# MKE15Z7 register map
Vendor: Freescale Semiconductor, Inc.; Series: Kinetis_E; File version: 1.6
CPU: CM0PLUS r0p0, little endian, no MPU, no FPU, VTOR, 2 interrupt priority bits
Registers are 32-bit, read-write, reset 0x0 unless marked. A register's access mark holds for its fields unless they carry their own. Offsets are from the block's base; [hi:lo] are bit positions.

## PWT — Pulse Width Timer
Base 0x40056000; register names take the prefix PWT_
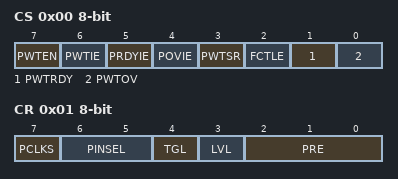
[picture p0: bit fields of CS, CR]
0x00 CS 8-bit — Pulse Width Timer Control and Status Register
  [7] PWTEN — PWT Module Enable
    0=The PWT is disabled; 1=The PWT is enabled
  [6] PWTIE — PWT Module Interrupt Enable
    0=Disables the PWT to generate interrupt; 1=Enables the PWT to generate interrupt
  [5] PRDYIE — PWT Pulse Width Data Ready Interrupt Enable
    0=Disable PWT to generate interrupt when PWTRDY is set; 1=Enable PWT to generate interrupt when PWTRDY is set
  [4] POVIE — PWT Counter Overflow Interrupt Enable
    0=Disable PWT to generate interrupt when PWTOV is set; 1=Enable PWT to generate interrupt when PWTOV is set
  [3] PWTSR wo — PWT Soft Reset
    0=No action taken; 1=Writing 1 to this field will perform soft reset to PWT
  [2] FCTLE — First counter load enable after enable
    0=Do not load the first counter values to corresponding registers; 1=Load the first coutner value to corresponding registers depended by the PWTIN level
  [1] PWTRDY — PWT Pulse Width Valid
    0=PWT pulse width register(s) is not up-to-date; 1=PWT pulse width register(s) has been updated
  [0] PWTOV — PWT Counter Overflow
    0=PWT counter no overflow; 1=PWT counter runs from 0xFFFF to 0x0000
0x01 CR 8-bit — Pulse Width Timer Control Register
  [7] PCLKS — PWT Clock Source Selection
    0=BUS_CLK is selected as the clock source of PWT counter; 1=Alternative clock is selected as the clock source of PWT counter
  [6:5] PINSEL — PWT Pulse Inputs Selection
    0=PWTIN[0] is enabled; 1=PWTIN[1] is enabled; 2=PWTIN[2] enabled; 3=PWTIN[3] enabled
  [4] TGL — PWTIN states Toggled from last state
    0=The selected PWTIN hasn't changed its original states from last time; 1=The selected PWTIN has toggled its states
  [3] LVL ro — PWTIN Level when Overflows
  [2:0] PRE — PWT Clock Prescaler (CLKPRE) Setting
    0=Clock divided by 1; 1=Clock divided by 2; 2=Clock divided by 4; 3=Clock divided by 8; 4=Clock divided by 16; 5=Clock divided by 32; 6=Clock divided by 64; 7=Clock divided by 128
0x02 PPH 8-bit ro — Pulse Width Timer Positive Pulse Width Register: High
  [7:0] PPWH — Positive Pulse Width[15:8]
0x03 PPL 8-bit ro — Pulse Width Timer Positive Pulse Width Register: Loq
  [7:0] PPWL — Positive Pulse Width[7:0]
0x04 NPH 8-bit ro — Pulse Width Timer Negative Pulse Width Register: High
  [7:0] NPWH — Negative Pulse Width[15:8]
0x05 NPL 8-bit ro — Pulse Width Timer Negative Pulse Width Register: Low
  [7:0] NPWL — Negative Pulse Width[7:0]
0x06 CNTH 8-bit ro — Pulse Width Timer Counter Register: High
  [7:0] PWTH — PWT counter[15:8]
0x07 CNTL 8-bit ro — Pulse Width Timer Counter Register: Low
  [7:0] PWTL — PWT counter[7:0]

## OSC32 — RTC Oscillator
Base 0x40060000; register names take the prefix OSC32_
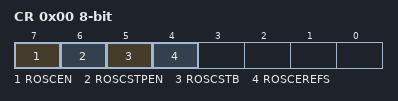
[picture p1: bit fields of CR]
0x00 CR 8-bit — RTC Oscillator Control Register
  [7] ROSCEN — RTC 32k Oscillator enable
    0=Oscillator is disabled; 1=Oscillator is enabled
  [6] ROSCSTPEN — RTC 32k Oscillator stop mode enable
    0=Oscillator is disabled regardless the state of ROSCEN; 1=Oscillator is enabled in Stop mode when ROSCEN is set
  [5] ROSCSTB ro — RTC 32k Oscillator stable flag
    0=RTC 32k oscillator is unstable now and no clock will go out of the block; 1=RTC 32k oscillator is stable
  [4] ROSCEREFS — RTC 32k Oscillator external reference clcok selection
    0=Bypass mode. RTC oscillator selects the external 32k clock.; 1=Crystal mode

## EWM — External Watchdog Monitor
Base 0x40061000; register names take the prefix EWM_
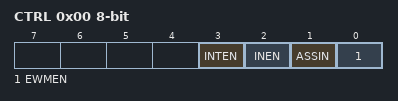
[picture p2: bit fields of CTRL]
0x00 CTRL 8-bit — Control Register
  [3] INTEN — Interrupt Enable.
  [2] INEN — Input Enable.
  [1] ASSIN — EWM_in's Assertion State Select.
  [0] EWMEN — EWM enable.
0x01 SERV 8-bit wo — Service Register
  [7:0] SERVICE — The EWM refresh mechanism requires the CPU to write two values to the SERV register: a first data byte of 0xB4, followed by a second data byte of 0x2C
0x02 CMPL 8-bit — Compare Low Register
  [7:0] COMPAREL — To prevent runaway code from changing this field, software should write to this field after a CPU reset even if the (default) minimum refresh time is required
0x03 CMPH 8-bit reset 0xFF — Compare High Register
  [7:0] COMPAREH — To prevent runaway code from changing this field, software should write to this field after a CPU reset even if the (default) maximum refresh time is required
0x05 CLKPRESCALER 8-bit — Clock Prescaler Register
  [7:0] CLK_DIV — Selected low power clock source for running the EWM counter can be prescaled as below
